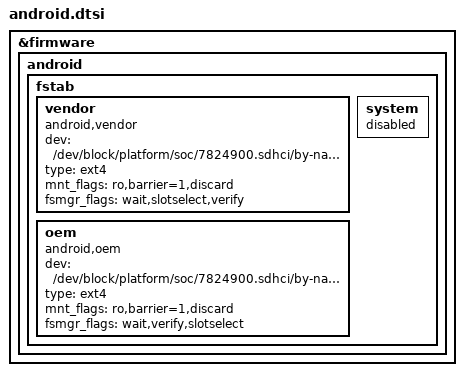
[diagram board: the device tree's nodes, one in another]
&firmware {
	android {
		fstab {
			vendor {
				compatible = "android,vendor";
				dev = "/dev/block/platform/soc/7824900.sdhci/by-name/vendor";
				type = "ext4";
				mnt_flags = "ro,barrier=1,discard";
				fsmgr_flags = "wait,slotselect,verify";
				status = "ok";
			};
                        oem {
				compatible = "android,oem";
				dev = "/dev/block/platform/soc/7824900.sdhci/by-name/oem";
				type = "ext4";
				mnt_flags = "ro,barrier=1,discard";
				fsmgr_flags = "wait,verify,slotselect";
				status = "ok";
                        };
			system {
				status = "disable";
			};
		};
	};
};
